# IWRL6432 register map
File version: 1.0
CPU: CM4 1.0, other endian, MPU, FPU, 3 interrupt priority bits
Registers are 32-bit, read-write, reset 0x0 unless marked. A register's access mark holds for its fields unless they carry their own. Offsets are from the block's base; [hi:lo] are bit positions; 'fields as' and 'values as' point back to an identical list.

## TPTC_A0 — Register test environment
Base 0x54000000
Same registers: TPTC_A1 0x54010000, TPTC_B0 0x55020000, TPTC_B0_1 0x55040000
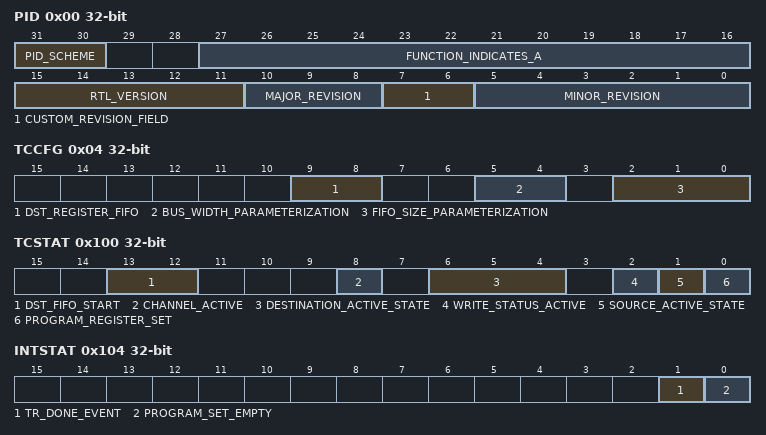
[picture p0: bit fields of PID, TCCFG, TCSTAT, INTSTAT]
0x00 PID — Peripheral ID Register
  [31:30] PID_SCHEME — [31:30] PID Scheme: Used to distinguish between old ID scheme and current. Spare bit to encode future schemes EDMA uses 'new scheme' indicated with value of 0x1.
  [27:16] FUNCTION_INDICATES_A — [27:16] Function indicates a software compatible module family.
  [15:11] RTL_VERSION — [15:11] RTL Version
  [10:8] MAJOR_REVISION — [10:8] Major Revision
  [7:6] CUSTOM_REVISION_FIELD — [7:6] Custom revision field: Not used on this version of EDMA.
  [5:0] MINOR_REVISION — [5:0] Minor Revision
0x04 TCCFG — TC Configuration Register
  [9:8] DST_REGISTER_FIFO — [9:8] Dst Register FIFO Depth Parameterization
  [5:4] BUS_WIDTH_PARAMETERIZATION — [5:4] Bus Width Parameterization
  [2:0] FIFO_SIZE_PARAMETERIZATION — [2:0] Fifo Size Parameterization
0x100 TCSTAT — TC Status Register
  [13:12] DST_FIFO_START — [13:12] Dst FIFO Start Pointer#br#Represents the offset to the head entry of Dst Register FIFO in units of entries. Legal values = 0x0 to 0x3
  [8] CHANNEL_ACTIVE — [8:8] Channel Active#br#Channel Active is a logical-OR of each of the BUSY/ACTV signals. The ACTV bit must remain high through the life of a TR.#br#ACTV = 0 : Channel is idle.#br#ACTV = 1 : Channel is busy.
  [6:4] DESTINATION_ACTIVE_STATE — [6:4] Destination Active State#br#Specifies the number of TRs that are resident in the Dst Register FIFO at a given instant.#br#Legal values are constrained by the DSTREGDEPTH parameter.
  [2] WRITE_STATUS_ACTIVE — [2:2] Write Status Active#br#WSACTV = 0 : Write status is not pending. Write status has been received for all previously issued write commands.#br#WSACTV = 1 : Write Status is pending. Write status has not been received for all previously issued write commands.
  [1] SOURCE_ACTIVE_STATE — [1:1] Source Active State#br#SRCACTV = 0 : Source Active set is idle. Any TR written to Prog Set will immediately transition to Source Active set as long as the Dst FIFO Set is not full [DSTFULL == 1].#br#SRCACTV = 1 : Source Active set is busy either performing read transfers or waiting to perform read transfers for current Transfer Request.
  [0] PROGRAM_REGISTER_SET — [0:0] Program Register Set Busy#br#PROGBUSY = 0 : Prog set idle and is available for programming.#br#PROGBUSY = 1 : Prog set busy. User should poll for PROGBUSY equal to '0' prior to re-programming the Program Register set.
0x104 INTSTAT — Interrupt Status Register
  [1] TR_DONE_EVENT — [1:1] TR Done Event Status:#br#TRDONE = 0 : Condition not detected.#br#TRDONE = 1 : Set when TC has completed a Transfer Request. TRDONE should be set when the write status is returned for the final write of a TR. Cleared when user writes '1' to INTCLR.TRDONE register bit.
  [0] PROGRAM_SET_EMPTY — [0:0] Program Set Empty Event Status:#br#PROGEMPTY = 0 : Condition not detected.#br#PROGEMPTY = 1 : Set when Program Register set transitions to empty state. Cleared when user writes '1' to INTCLR.PROGEMPTY register bit.
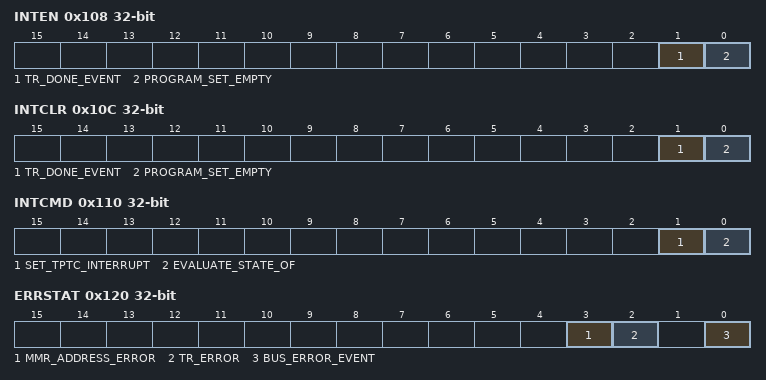
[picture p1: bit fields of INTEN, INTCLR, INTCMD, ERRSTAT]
0x108 INTEN — Interrupt Enable Register
  [1] TR_DONE_EVENT — [1:1] TR Done Event Enable:#br#INTEN.TRDONE = 0 : TRDONE Event is disabled.#br#INTEN.TRDONE = 1 : TRDONE Event is enabled and contributes to interrupt generation
  [0] PROGRAM_SET_EMPTY — [0:0] Program Set Empty Event Enable:#br#INTEN.PROGEMPTY = 0 : PROGEMPTY Event is disabled.#br#INTEN.PROGEMPTY = 1 : PROGEMPTY Event is enabled and contributes to interrupt generation
0x10C INTCLR — Interrupt Clear Register
  [1] TR_DONE_EVENT — [1:1] TR Done Event Clear:#br#INTCLR.TRDONE = 0 : Writes of '0' have no effect.#br#INTCLR.TRDONE = 1 : Write of '1' clears INTSTAT.TRDONE bit
  [0] PROGRAM_SET_EMPTY — [0:0] Program Set Empty Event Clear:#br#INTCLR.PROGEMPTY = 0 : Writes of '0' have no effect.#br#INTCLR.PROGEMPTY = 1 : Write of '1' clears INTSTAT.PROGEMPTY bit
0x110 INTCMD — Interrupt Command Register
  [1] SET_TPTC_INTERRUPT — [1:1] Set TPTC interrupt:#br#Write of '1' to SET causes TPTC interrupt to be pulsed unconditionally.#br#Writes of '0' have no affect.
  [0] EVALUATE_STATE_OF — [0:0] Evaluate state of TPTC interrupt#br#Write of '1' to EVAL causes TPTC interrupt to be pulsed if any of the INTSTAT bits are set to '1'.#br#Writes of '0' have no affect.
0x120 ERRSTAT — Error Status Register
  [3] MMR_ADDRESS_ERROR — [3:3] MMR Address Error:#br#MMRAERR = 0 : Condition not detected.#br#MMRAERR = 1 : User attempted to read or write to invalid address configuration memory map. [Is only be set for non-emulation accesses]. No additional error information is recorded.
  [2] TR_ERROR — [2:2] TR Error:#br#TR detected that violates FIFO Mode transfer [SAM or DAM is '1'] alignment rules or has ACNT or BCNT == 0. No additional error information is recorded.
  [0] BUS_ERROR_EVENT — [0:0] Bus Error Event:#br#BUSERR = 0: Condition not detected.#br#BUSERR = 1: TC has detected an error code on the write response bus or read response bus. Error information is stored in Error Details Register [ERRDET].
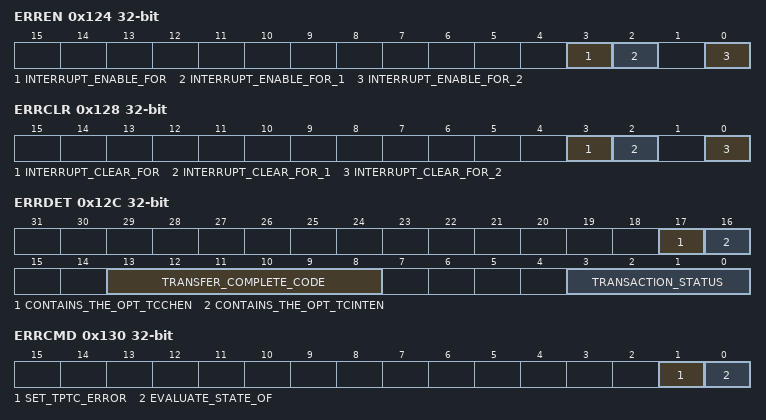
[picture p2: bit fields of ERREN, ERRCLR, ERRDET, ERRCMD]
0x124 ERREN — Error Enable Register
  [3] INTERRUPT_ENABLE_FOR — [3:3] Interrupt enable for ERRSTAT.MMRAERR:#br#ERREN.MMRAERR = 0 : BUSERR is disabled.#br#ERREN.MMRAERR = 1 : MMRAERR is enabled and contributes to the TPTC error interrupt generation.
  [2] INTERRUPT_ENABLE_FOR_1 — [2:2] Interrupt enable for ERRSTAT.TRERR:#br#ERREN.TRERR = 0 : BUSERR is disabled.#br#ERREN.TRERR = 1 : TRERR is enabled and contributes to the TPTC error interrupt generation.
  [0] INTERRUPT_ENABLE_FOR_2 — [0:0] Interrupt enable for ERRSTAT.BUSERR:#br#ERREN.BUSERR = 0 : BUSERR is disabled.#br#ERREN.BUSERR = 1 : BUSERR is enabled and contributes to the TPTC error interrupt generation.
0x128 ERRCLR — Error Clear Register
  [3] INTERRUPT_CLEAR_FOR — [3:3] Interrupt clear for ERRSTAT.MMRAERR:#br#ERRCLR.MMRAERR = 0 : Writes of '0' have no effect.#br#ERRCLR.MMRAERR = 1 : Write of '1' clears ERRSTAT.MMRAERR bit. Write of '1' to ERRCLR.MMRAERR does not clear the ERRDET register.
  [2] INTERRUPT_CLEAR_FOR_1 — [2:2] Interrupt clear for ERRSTAT.TRERR:#br#ERRCLR.TRERR = 0 : Writes of '0' have no effect.#br#ERRCLR.TRERR = 1 : Write of '1' clears ERRSTAT.TRERR bit. Write of '1' to ERRCLR.TRERR does not clear the ERRDET register.
  [0] INTERRUPT_CLEAR_FOR_2 — [0:0] Interrupt clear for ERRSTAT.BUSERR:#br#ERRCLR.BUSERR = 0 : Writes of '0' have no effect.#br#ERRCLR.BUSERR = 1 : Write of '1' clears ERRSTAT.BUSERR bit. Write of '1' to ERRCLR.BUSERR clears the ERRDET register.
0x12C ERRDET — Error Details Register
  [17] CONTAINS_THE_OPT_TCCHEN — [17:17] Contains the OPT.TCCHEN value programmed by the user for the Read or Write transaction that resulted in an error.
  [16] CONTAINS_THE_OPT_TCINTEN — [16:16] Contains the OPT.TCINTEN value programmed by the user for the Read or Write transaction that resulted in an error.
  [13:8] TRANSFER_COMPLETE_CODE — [13:8] Transfer Complete Code: Contains the OPT.TCC value programmed by the user for the Read or Write transaction that resulted in an error.
  [3:0] TRANSACTION_STATUS — [3:0] Transaction Status:#br#Stores the non-zero status/error code that was detected on the read status or write status bus.#br#MS-bit effectively serves as the read vs. write error code.#br#If read status and write status are returned on the same cycle then the TC chooses non-zero version. If both are non-zero then write status is treated as higher priority.#br#Encoding of errors matches the CBA spec.
0x130 ERRCMD — Error Command Register
  [1] SET_TPTC_ERROR — [1:1] Set TPTC error interrupt:#br#Write of '1' to SET causes TPTC error interrupt to be pulsed unconditionally.#br#Writes of '0' have no affect.
  [0] EVALUATE_STATE_OF — [0:0] Evaluate state of TPTC error interrupt#br#Write of '1' to EVAL causes TPTC error interrupt to be pulsed if any of the ERRSTAT bits are set to '1'.#br#Writes of '0' have no affect.
0x140 RDRATE — Read Rate Register
  [2:0] READ_RATE_CONTROL — [2:0] Read Rate Control: Controls the number of cycles between read commands. This is a global setting that applies to all TRs for this TC.
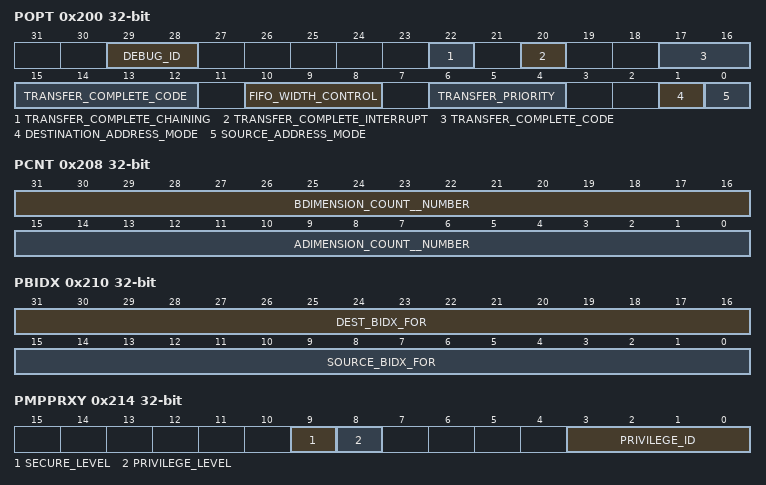
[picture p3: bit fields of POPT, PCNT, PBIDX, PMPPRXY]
0x200 POPT — Prog Set Options
  [29:28] DEBUG_ID — [29:28] Debug ID#br#Value driven on the read (tptc_r_dbg_channel_id) and write (tptc_w_dbg_channel_id) command bus.#br#Used at system level for trace/profiling of user selected transfers in systems that include this feature.
  [22] TRANSFER_COMPLETE_CHAINING — [22:22] Transfer complete chaining enable:#br#0: Transfer complete chaining is disabled.#br#1: Transfer complete chaining is enabled.
  [20] TRANSFER_COMPLETE_INTERRUPT — [20:20] Transfer complete interrupt enable:#br#0: Transfer complete interrupt is disabled.#br#1: Transfer complete interrupt is enabled.
  [17:12] TRANSFER_COMPLETE_CODE — [17:12] Transfer Complete Code: The 6-bit code is used to set the relevant bit in CER or IPR of the TPCC module.
  [10:8] FIFO_WIDTH_CONTROL — [10:8] FIFO width control: Applies if either SAM or DAM is set to FIFO mode.
  [6:4] TRANSFER_PRIORITY — [6:4] Transfer Priority:#br#0: Priority 0 - Highest priority#br#1: Priority 1 ...#br#7: Priority 7 - Lowest priority
  [1] DESTINATION_ADDRESS_MODE — [1:1] Destination Address Mode within an array:#br#0: INCR Dst addressing within an array increments.#br#1: FIFO Dst addressing within an array wraps around upon reaching FIFO width.
  [0] SOURCE_ADDRESS_MODE — [0:0] Source Address Mode within an array:#br#0: INCR Src addressing within an array increments.#br#1: FIFO Src addressing within an array wraps around upon reaching FIFO width.
0x204 PSRC — Prog Set Src Address
  [31:0] SOURCE_ADDRESS_FOR — [31:0] Source address for Program Register Set
0x208 PCNT — Prog Set Count
  [31:16] BDIMENSION_COUNT__NUMBER — [31:16] B-Dimension count. Number of arrays to be transferred where each array is ACNT in length.
  [15:0] ADIMENSION_COUNT__NUMBER — [15:0] A-Dimension count. Number of bytes to be transferred in first dimension.
0x20C PDST — Prog Set Dst Address
  [31:0] DESTINATION_ADDRESS_FOR — [31:0] Destination address for Program Register Set
0x210 PBIDX — Prog Set B-Dim Idx
  [31:16] DEST_BIDX_FOR — [31:16] Dest B-Idx for Program Register Set:#br#B-Idx offset between Destination arrays: Represents the offset in bytes between the starting address of each destination array [recall that there are BCNT arrays of ACNT elements]. DBIDX is always used regardless of whether DAM is Increment or FIFO mode.
  [15:0] SOURCE_BIDX_FOR — [15:0] Source B-Idx for Program Register Set:#br#B-Idx offset between Source arrays: Represents the offset in bytes between the starting address of each source array [recall that there are BCNT arrays of ACNT elements]. SBIDX is always used regardless of whether SAM is Increment or FIFO mode.
0x214 PMPPRXY — Prog Set Mem Protect Proxy
  [9] SECURE_LEVEL — [9:9] Secure Level: Deprecated, always read as 0.
  [8] PRIVILEGE_LEVEL — [8:8] Privilege Level:#br#PRIV = 0 : User level privilege#br#PRIV = 1 : Supervisor level privilege#br#PMPPRXY.PRIV is always updated with the value from the configuration bus privilege field on any/every write to Program Set BIDX Register [trigger register].#br#The PRIV value for the SA Set and DF Set are copied from the value in the Program set along with the remainder of the parameter values.The privilege ID is issued on the VBusM read and write command bus such that the target endpoints can perform memory protection checks based on the PRIV of the external host that sets up the DMA transaction.
  [3:0] PRIVILEGE_ID — [3:0] Privilege ID:#br#PMPPRXY.PRIVID is always updated with the value from configuration bus privilege ID field on any/every write to Program Set BIDX Register [trigger register].#br#The PRIVID value for the SA Set and DF Set are copied from the value in the Program set along with the remainder of the parameter values.The privilege ID is issued on the VBusM read and write command bus such that the target endpoints can perform memory protection checks based on the privid of the external host that sets up the DMA transaction.
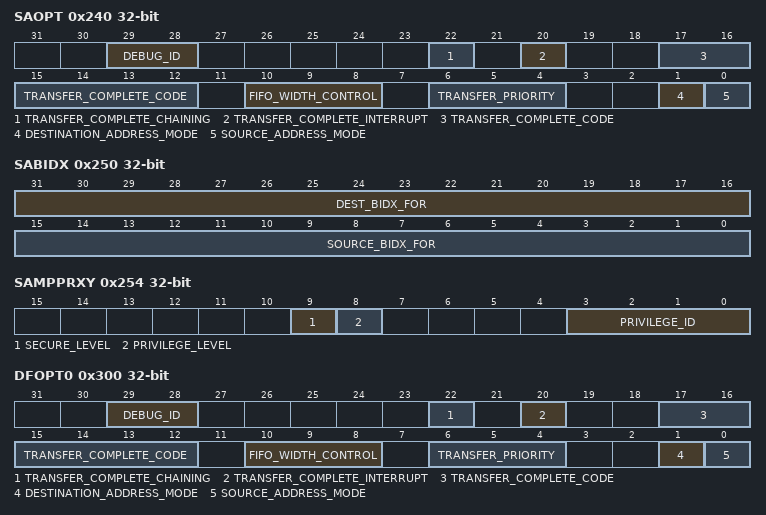
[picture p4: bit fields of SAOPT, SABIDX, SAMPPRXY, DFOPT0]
0x240 SAOPT — Src Actv Set Options
  fields as POPT
0x244 SASRC — Src Actv Set Src Address
  [31:0] SOURCE_ADDRESS_FOR_1 — [31:0] Source address for Source Active Register Set
0x248 SACNT — Src Actv Set A-Count
  [22:0] ADIMENSION_COUNT__NUMBER — [22:0] A-Dimension count. Number of bytes to be transferred in first dimension.
0x24C SADST — Src Actv Set Dst Address
  [31:0] DESTINATION_ADDRESS_FOR_1 — [31:0] Destination address for Source Active Register Set
0x250 SABIDX — Src Actv Set B-Dim Idx
  [31:16] DEST_BIDX_FOR — [31:16] Dest B-Idx for Source Active Register Set:#br#B-Idx offset between Destination arrays: Represents the offset in bytes between the starting address of each destination array [recall that there are BCNT arrays of ACNT elements]. DBIDX is always used regardless of whether DAM is Increment or FIFO mode.
  [15:0] SOURCE_BIDX_FOR — [15:0] Source B-Idx for Source Active Register Set:#br#B-Idx offset between Source arrays: Represents the offset in bytes between the starting address of each source array [recall that there are BCNT arrays of ACNT elements]. SBIDX is always used regardless of whether SAM is Increment or FIFO mode.
0x254 SAMPPRXY — Src Actv Set Mem Protect Proxy
  fields as PMPPRXY
0x258 SACNTRLD — Src Actv Set Cnt Reload
  [15:0] ACNT_RELOAD_VALUE — [15:0] A-Cnt Reload value for Source Active Register set. Value copied from PCNT.ACNT: Represents the originally programmed value of ACNT.#br#The Reload value is used to reinitialize ACNT after each array is serviced [i.e. ACNT decrements to 0]. by the Src offset in bytes between the starting address of each source array [recall that there are BCNT arrays of ACNT bytes]
0x25C SASRCBREF — Src Actv Set Src Addr B-Reference
  [31:0] SOURCE_ADDRESS_REFERENCE — [31:0] Source address reference for Source Active Register Set:#br#Represents the starting address for the array currently being read. The next array's starting address is calculated as the 'reference address' plus the 'source b-idx' value.
0x260 SADSTBREF — Src Actv Set Dst Addr B-Reference
  [31:0] DST_ADDRESS_REFERENCE — [31:0] Dst address reference is not applicable for Src Active Register Set. Reads return 0x0.
0x264 SABCNT — Src Actv Set B-Count
  [15:0] BDIMENSION_COUNT — [15:0] B-Dimension count:#br#Number of arrays to be transferred where each array is ACNT in length.#br#Count Remaining for Src Active Register Set. Represents the amount of data remaining to be read. Initial value is copied from PCNT. TC decrements ACNT and BCNT as necessary after each read command is issued. Final value should be 0 when TR is complete.
0x280 DFCNTRLD — Dst FIFO Set Cnt Reload
  [15:0] ACNT_RELOAD_VALUE_1 — [15:0] A-Cnt Reload value for Destination FIFO Register set. Value copied from PCNT.ACNT: Represents the originally programmed value of ACNT.#br#The Reload value is used to reinitialize ACNT after each array is serviced [i.e. ACNT decrements to 0]. by the Src offset in bytes between the starting address of each source array [recall that there are BCNT arrays of ACNT bytes]
0x284 DFSRCBREF — Dst FIFO Set Src Addr B-Reference
  [31:0] SOURCE_ADDRESS_REFERENCE_1 — [31:0] Source address reference for Destination FIFO Register Set:#br#Represents the starting address for the array currently being read. The next array's starting address is calculated as the 'reference address' plus the 'source b-idx' value.
0x300 DFOPT0 — Dst FIFO Set Options
  fields as POPT
0x304 DFSRC0 — Dst FIFO Set Src Address
  [31:0] SOURCE_ADDRESS_IS — [31:0] Source address is not applicable for Dst FIFO Register Set: Reads return 0x0.
0x308 DFACNT0 — Dst FIFO Set A-Count
  [22:0] ADIMENSION_COUNT__NUMBER_1 — [22:0] A-Dimension count. Number of bytes to be transferred infirst dimension.
0x30C DFDST0 — Dst FIFO Set Dst Address
  [31:0] DESTINATION_ADDRESS_FOR_2 — [31:0] Destination address for Dst FIFO Register Set:#br#Initial value is copied from PDST.DADDR.#br#TC updates value according to destination addressing mode [OPT.SAM] and/or dest index value [BIDX.DBIDX] after each write command is issued.#br#When a TR is complete the final value should be the address of the last write command issued.
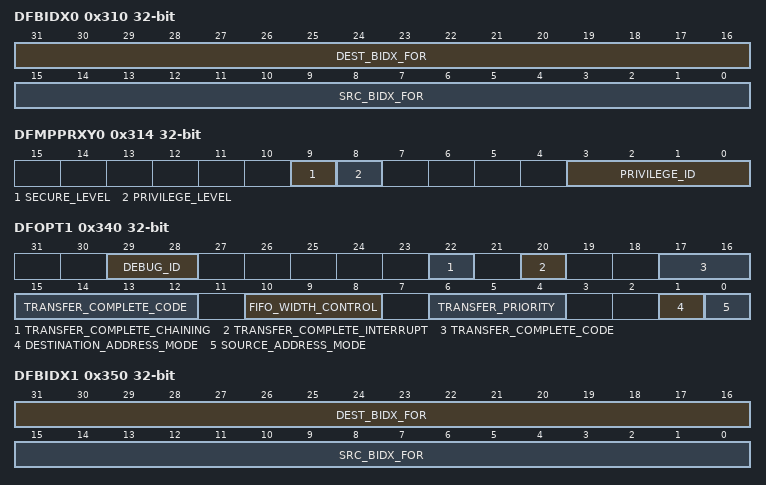
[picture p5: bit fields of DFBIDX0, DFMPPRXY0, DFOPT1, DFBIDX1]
0x310 DFBIDX0 — Dst FIFO Set B-Dim Idx
  [31:16] DEST_BIDX_FOR — [31:16] Dest B-Idx for Dest FIFO Register Set.#br#Value copied from PBIDX: B-Idx offset between Destination arrays: Represents the offset in bytes between the starting address of each destination array [recall that there are BCNT arrays of ACNT elements].#br#DBIDX is always used regardless of whether DAM is Increment or FIFO mode.
  [15:0] SRC_BIDX_FOR — [15:0] Src B-Idx for Dest FIFO Register Set.#br#Value copied from PBIDX: B-Idx offset between Source arrays: Represents the offset in bytes between the starting address of each source array [recall that there are BCNT arrays of ACNT elements].#br#SBIDX is always used regardless of whether SAM is Increment or FIFO mode.
0x314 DFMPPRXY0 — Dst FIFO Set Mem Protect Proxy
  fields as PMPPRXY
0x318 DFBCNT0 — Dst FIFO Set B-Count
  [15:0] BCOUNT_REMAINING_FOR — [15:0] B-Count Remaining for Dst Register Set:#br#Number of arrays to be transferred where each array is ACNT in length.#br#Represents the amount of data remaining to be written.#br#Initial value is copied from PCNT.#br#TC decrements ACNT and BCNT as necessary after each write dataphase is issued. Final value should be 0 when TR is complete.
0x340 DFOPT1 — Dst FIFO Set Options
  fields as POPT
0x344 DFSRC1 — Dst FIFO Set Src Address
  [31:0] SOURCE_ADDRESS_IS_1 — [31:0] Source address is not applicable for Dst FIFO Register Set: Reads return 0x0.
0x348 DFACNT1 — Dst FIFO Set A-Count
  [22:0] ADIMENSION_COUNT__NUMBER_2 — [22:0] A-Dimension count. Number of bytes to be transferred infirst dimension.
0x34C DFDST1 — Dst FIFO Set Dst Address
  [31:0] DESTINATION_ADDRESS_FOR_3 — [31:0] Destination address for Dst FIFO Register Set:#br#Initial value is copied from PDST.DADDR.#br#TC updates value according to destination addressing mode [OPT.SAM] and/or dest index value [BIDX.DBIDX] after each write command is issued.#br#When a TR is complete the final value should be the address of the last write command issued.
0x350 DFBIDX1 — Dst FIFO Set B-Dim Idx
  fields as DFBIDX0
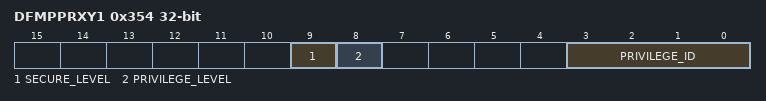
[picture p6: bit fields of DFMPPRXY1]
0x354 DFMPPRXY1 — Dst FIFO Set Mem Protect Proxy
  fields as PMPPRXY
0x358 DFBCNT1 — Dst FIFO Set B-Count
  [15:0] BCOUNT_REMAINING_FOR_1 — [15:0] B-Count Remaining for Dst Register Set:#br#Number of arrays to be transferred where each array is ACNT in length.#br#Represents the amount of data remaining to be written.#br#Initial value is copied from PCNT.#br#TC decrements ACNT and BCNT as necessary after each write dataphase is issued. Final value should be 0 when TR is complete.
